# STM32F407ZGT7 register map
File version: 1.0
Registers are 32-bit, access not given, reset 0x0 unless marked. A register's access mark holds for its fields unless they carry their own. Offsets are from the block's base; [hi:lo] are bit positions; {n}, {i} and the like mark numbered series; 'fields as' and 'values as' point back to an identical list.

## USB_OTG_HS
Base 0x40040000
Same registers: USB_OTG_FS 0x50000000
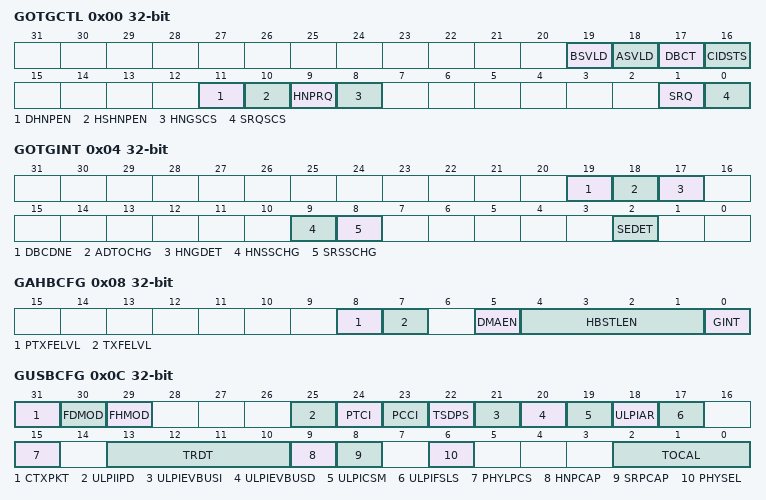
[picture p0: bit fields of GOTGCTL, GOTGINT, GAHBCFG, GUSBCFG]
0x00 GOTGCTL
  [19] BSVLD, [18] ASVLD, [17] DBCT, [16] CIDSTS, [11] DHNPEN, [10] HSHNPEN, [9] HNPRQ, [8] HNGSCS, [1] SRQ, [0] SRQSCS
0x04 GOTGINT
  [19] DBCDNE, [18] ADTOCHG, [17] HNGDET, [9] HNSSCHG, [8] SRSSCHG, [2] SEDET
0x08 GAHBCFG
  [8] PTXFELVL, [7] TXFELVL, [5] DMAEN, [4:1] HBSTLEN, [0] GINT
0x0C GUSBCFG
  [31] CTXPKT, [30] FDMOD, [29] FHMOD, [25] ULPIIPD, [24] PTCI, [23] PCCI, [22] TSDPS, [21] ULPIEVBUSI, [20] ULPIEVBUSD, [19] ULPICSM, [18] ULPIAR, [17] ULPIFSLS, [15] PHYLPCS, [13:10] TRDT, [9] HNPCAP, [8] SRPCAP, [6] PHYSEL, [2:0] TOCAL
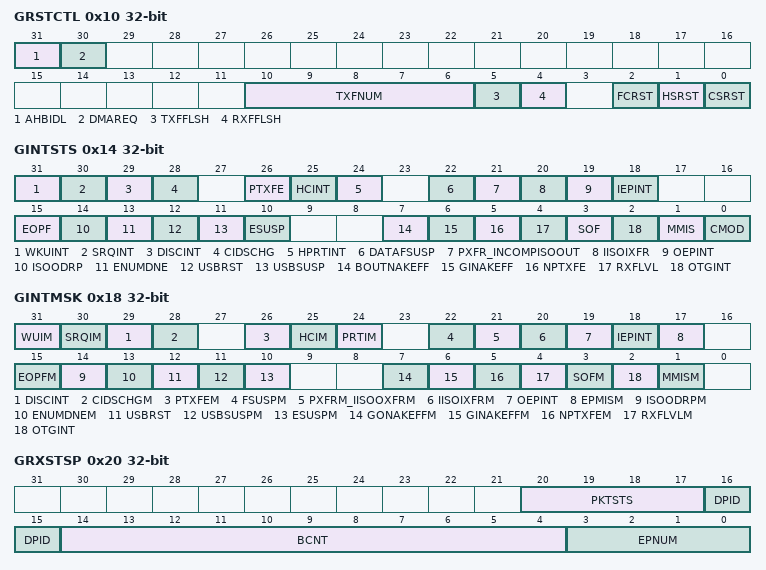
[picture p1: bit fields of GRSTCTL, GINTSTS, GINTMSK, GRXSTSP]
0x10 GRSTCTL
  [31] AHBIDL, [30] DMAREQ, [10:6] TXFNUM, [5] TXFFLSH, [4] RXFFLSH, [2] FCRST, [1] HSRST, [0] CSRST
0x14 GINTSTS
  [31] WKUINT, [30] SRQINT, [29] DISCINT, [28] CIDSCHG, [26] PTXFE, [25] HCINT, [24] HPRTINT, [22] DATAFSUSP, [21] PXFR_INCOMPISOOUT, [20] IISOIXFR, [19] OEPINT, [18] IEPINT, [15] EOPF, [14] ISOODRP, [13] ENUMDNE, [12] USBRST, [11] USBSUSP, [10] ESUSP, [7] BOUTNAKEFF, [6] GINAKEFF, [5] NPTXFE, [4] RXFLVL, [3] SOF, [2] OTGINT, [1] MMIS, [0] CMOD
0x18 GINTMSK
  [31] WUIM, [30] SRQIM, [29] DISCINT, [28] CIDSCHGM, [26] PTXFEM, [25] HCIM, [24] PRTIM, [22] FSUSPM, [21] PXFRM_IISOOXFRM, [20] IISOIXFRM, [19] OEPINT, [18] IEPINT, [17] EPMISM, [15] EOPFM, [14] ISOODRPM, [13] ENUMDNEM, [12] USBRST, [11] USBSUSPM, [10] ESUSPM, [7] GONAKEFFM, [6] GINAKEFFM, [5] NPTXFEM, [4] RXFLVLM, [3] SOFM, [2] OTGINT, [1] MMISM
0x1C GRXSTSR
0x20 GRXSTSP
  [20:17] PKTSTS, [16:15] DPID, [14:4] BCNT, [3:0] EPNUM
0x24 GRXFSIZ
  [15:0] RXFD
0x28 DIEPTXF0_HNPTXFSIZ
0x2C HNPTXSTS
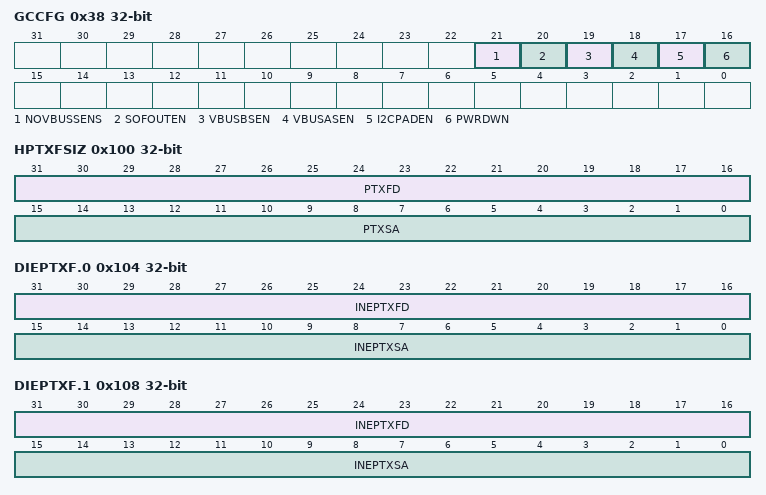
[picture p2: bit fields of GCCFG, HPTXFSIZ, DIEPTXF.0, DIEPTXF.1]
0x38 GCCFG
  [21] NOVBUSSENS, [20] SOFOUTEN, [19] VBUSBSEN, [18] VBUSASEN, [17] I2CPADEN, [16] PWRDWN
0x3C CID
  [31:0] PRODUCT_ID
0x100 HPTXFSIZ
  [31:16] PTXFD, [15:0] PTXSA
0x104 DIEPTXF.0
  [31:16] INEPTXFD, [15:0] INEPTXSA
0x108 DIEPTXF.1
  [31:16] INEPTXFD, [15:0] INEPTXSA
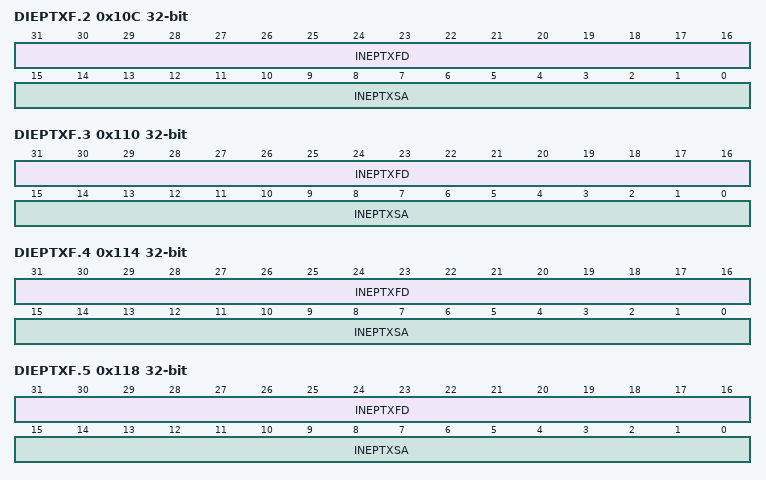
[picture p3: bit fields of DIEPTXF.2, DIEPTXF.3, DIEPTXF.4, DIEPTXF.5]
0x10C DIEPTXF.2
  [31:16] INEPTXFD, [15:0] INEPTXSA
0x110 DIEPTXF.3
  [31:16] INEPTXFD, [15:0] INEPTXSA
0x114 DIEPTXF.4
  [31:16] INEPTXFD, [15:0] INEPTXSA
0x118 DIEPTXF.5
  [31:16] INEPTXFD, [15:0] INEPTXSA
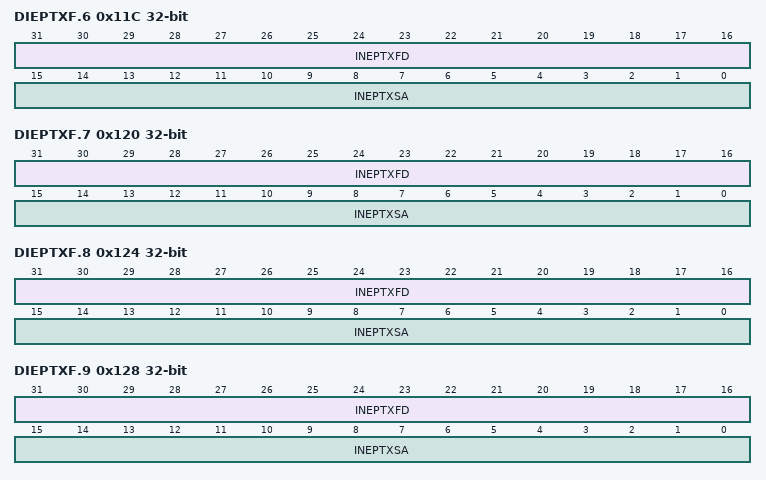
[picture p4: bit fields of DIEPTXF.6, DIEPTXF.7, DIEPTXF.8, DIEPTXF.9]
0x11C DIEPTXF.6
  [31:16] INEPTXFD, [15:0] INEPTXSA
0x120 DIEPTXF.7
  [31:16] INEPTXFD, [15:0] INEPTXSA
0x124 DIEPTXF.8
  [31:16] INEPTXFD, [15:0] INEPTXSA
0x128 DIEPTXF.9
  [31:16] INEPTXFD, [15:0] INEPTXSA
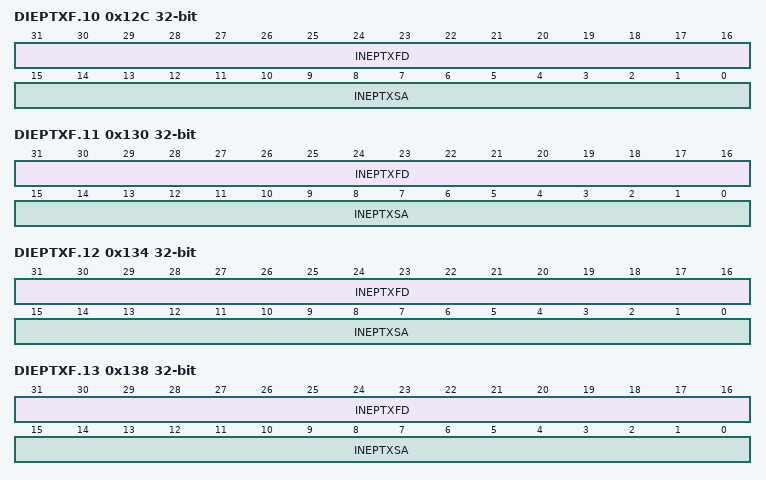
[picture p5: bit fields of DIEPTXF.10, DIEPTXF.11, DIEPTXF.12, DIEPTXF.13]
0x12C DIEPTXF.10
  [31:16] INEPTXFD, [15:0] INEPTXSA
0x130 DIEPTXF.11
  [31:16] INEPTXFD, [15:0] INEPTXSA
0x134 DIEPTXF.12
  [31:16] INEPTXFD, [15:0] INEPTXSA
0x138 DIEPTXF.13
  [31:16] INEPTXFD, [15:0] INEPTXSA
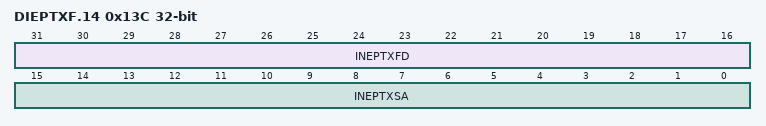
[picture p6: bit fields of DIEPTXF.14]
0x13C DIEPTXF.14
  [31:16] INEPTXFD, [15:0] INEPTXSA

## DCMI
Base 0x50050000
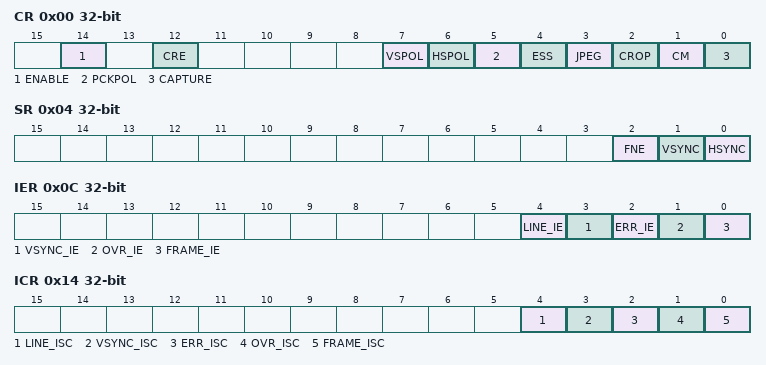
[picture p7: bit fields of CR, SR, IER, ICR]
0x00 CR
  [14] ENABLE, [12] CRE, [7] VSPOL, [6] HSPOL, [5] PCKPOL, [4] ESS, [3] JPEG, [2] CROP, [1] CM, [0] CAPTURE
0x04 SR
  [2] FNE, [1] VSYNC, [0] HSYNC
0x08 RISR
0x0C IER
  [4] LINE_IE, [3] VSYNC_IE, [2] ERR_IE, [1] OVR_IE, [0] FRAME_IE
0x10 MISR
0x14 ICR
  [4] LINE_ISC, [3] VSYNC_ISC, [2] ERR_ISC, [1] OVR_ISC, [0] FRAME_ISC
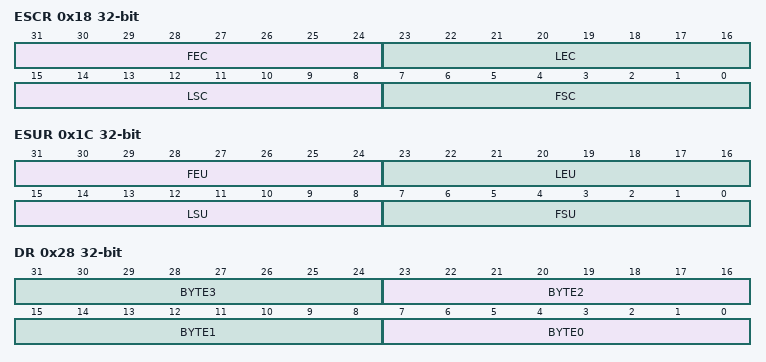
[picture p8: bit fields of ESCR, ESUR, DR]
0x18 ESCR
  [31:24] FEC, [23:16] LEC, [15:8] LSC, [7:0] FSC
0x1C ESUR
  [31:24] FEU, [23:16] LEU, [15:8] LSU, [7:0] FSU
0x20 CWSTRTR
0x24 CWSIZER
0x28 DR
  [8n+7:8n] BYTE{n} (n=0..3)

## RNG
Base 0x50060800
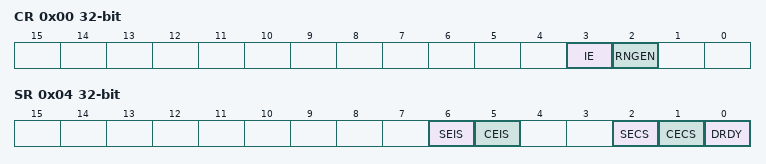
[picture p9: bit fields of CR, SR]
0x00 CR
  [3] IE, [2] RNGEN
0x04 SR
  [6] SEIS, [5] CEIS, [2] SECS, [1] CECS, [0] DRDY
0x08 DR

## FSMC_Bank1
Base 0xA0000000
0x00 BTCR.0
0x04 BTCR.1
0x08 BTCR.2
0x0C BTCR.3
0x10 BTCR.4
0x14 BTCR.5
0x18 BTCR.6
0x1C BTCR.7

## FSMC_Bank2_3
Base 0xA0000060
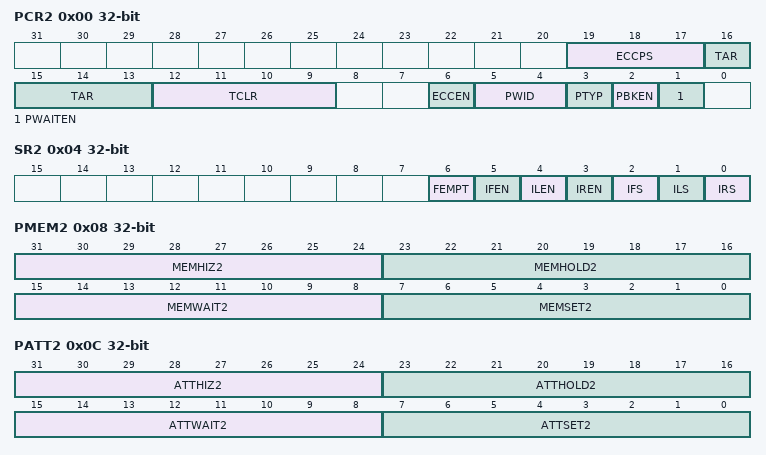
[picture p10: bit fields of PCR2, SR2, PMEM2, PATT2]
0x00 PCR2
  [19:17] ECCPS, [16:13] TAR, [12:9] TCLR, [6] ECCEN, [5:4] PWID, [3] PTYP, [2] PBKEN, [1] PWAITEN
0x04 SR2
  [6] FEMPT, [5] IFEN, [4] ILEN, [3] IREN, [2] IFS, [1] ILS, [0] IRS
0x08 PMEM2
  [31:24] MEMHIZ2, [23:16] MEMHOLD2, [15:8] MEMWAIT2, [7:0] MEMSET2
0x0C PATT2
  [31:24] ATTHIZ2, [23:16] ATTHOLD2, [15:8] ATTWAIT2, [7:0] ATTSET2
0x14 ECCR2
  [31:0] ECC2
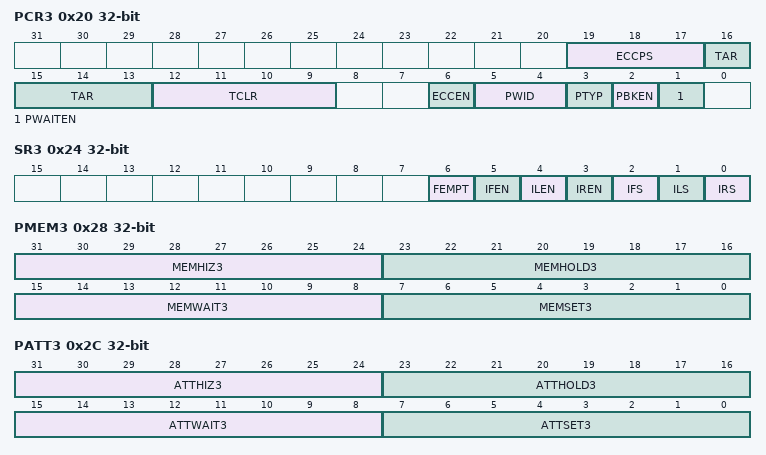
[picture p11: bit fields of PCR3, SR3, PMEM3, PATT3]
0x20 PCR3
  fields as PCR2
0x24 SR3
  [6] FEMPT, [5] IFEN, [4] ILEN, [3] IREN, [2] IFS, [1] ILS, [0] IRS
0x28 PMEM3
  [31:24] MEMHIZ3, [23:16] MEMHOLD3, [15:8] MEMWAIT3, [7:0] MEMSET3
0x2C PATT3
  [31:24] ATTHIZ3, [23:16] ATTHOLD3, [15:8] ATTWAIT3, [7:0] ATTSET3
0x34 ECCR3
  [31:0] ECC3

## FSMC_Bank4
Base 0xA00000A0
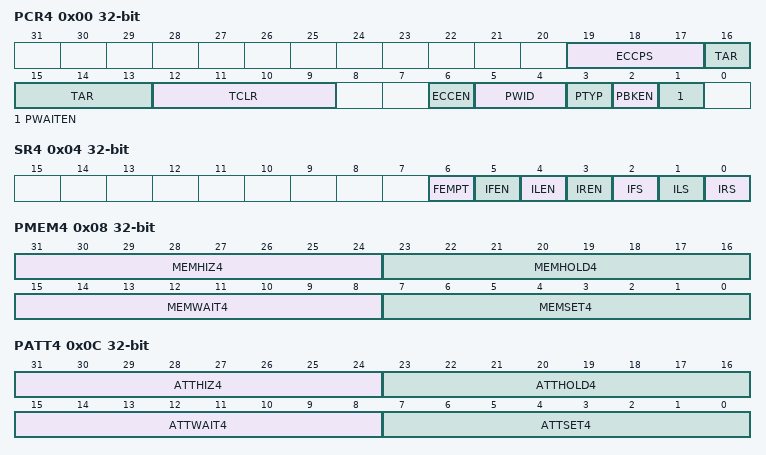
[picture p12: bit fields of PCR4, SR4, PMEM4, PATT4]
0x00 PCR4
  [19:17] ECCPS, [16:13] TAR, [12:9] TCLR, [6] ECCEN, [5:4] PWID, [3] PTYP, [2] PBKEN, [1] PWAITEN
0x04 SR4
  [6] FEMPT, [5] IFEN, [4] ILEN, [3] IREN, [2] IFS, [1] ILS, [0] IRS
0x08 PMEM4
  [31:24] MEMHIZ4, [23:16] MEMHOLD4, [15:8] MEMWAIT4, [7:0] MEMSET4
0x0C PATT4
  [31:24] ATTHIZ4, [23:16] ATTHOLD4, [15:8] ATTWAIT4, [7:0] ATTSET4
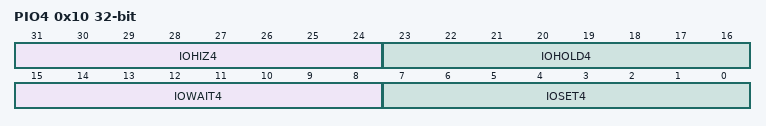
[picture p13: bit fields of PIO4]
0x10 PIO4
  [31:24] IOHIZ4, [23:16] IOHOLD4, [15:8] IOWAIT4, [7:0] IOSET4

## FSMC_Bank1E
Base 0xA0000104
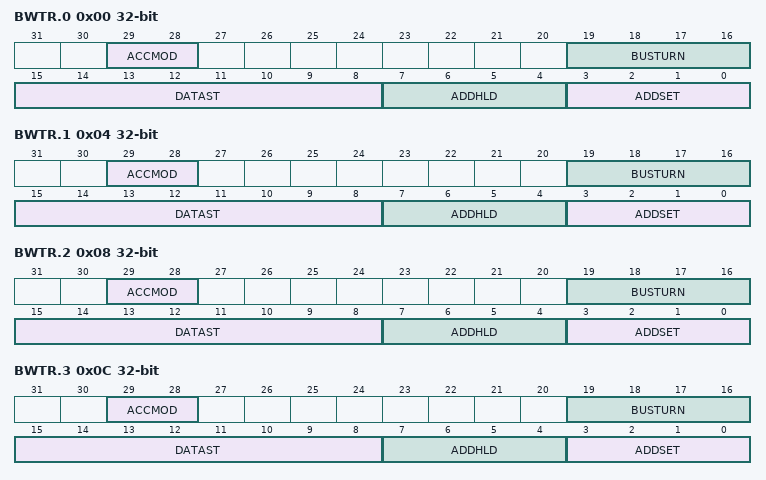
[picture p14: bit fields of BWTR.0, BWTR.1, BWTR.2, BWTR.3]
0x00 BWTR.0
  [29:28] ACCMOD, [19:16] BUSTURN, [15:8] DATAST, [7:4] ADDHLD, [3:0] ADDSET
0x04 BWTR.1
  fields as BWTR.0
0x08 BWTR.2
  fields as BWTR.0
0x0C BWTR.3
  fields as BWTR.0
0x10 BWTR.4
0x14 BWTR.5
0x18 BWTR.6

## DBGMCU
Base 0xE0042000
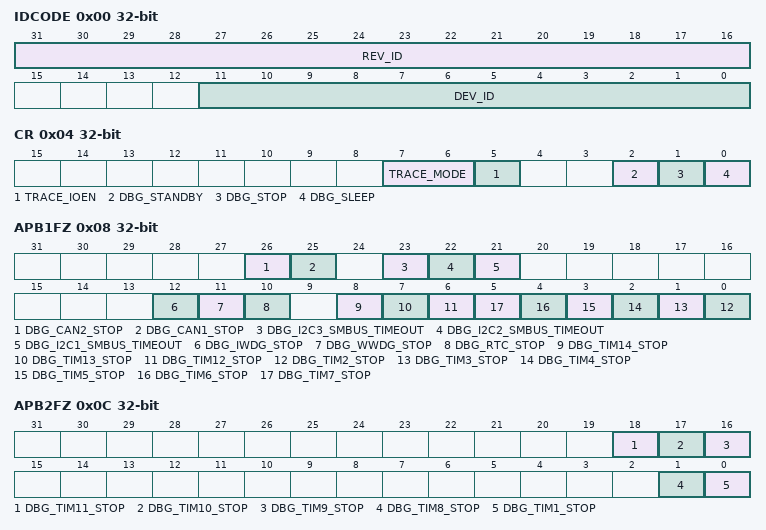
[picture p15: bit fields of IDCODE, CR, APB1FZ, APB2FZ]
0x00 IDCODE
  [31:16] REV_ID, [11:0] DEV_ID
0x04 CR
  [7:6] TRACE_MODE, [5] TRACE_IOEN, [2] DBG_STANDBY, [1] DBG_STOP, [0] DBG_SLEEP
0x08 APB1FZ
  [26] DBG_CAN2_STOP, [25] DBG_CAN1_STOP, [23] DBG_I2C3_SMBUS_TIMEOUT, [22] DBG_I2C2_SMBUS_TIMEOUT, [21] DBG_I2C1_SMBUS_TIMEOUT, [12] DBG_IWDG_STOP, [11] DBG_WWDG_STOP, [10] DBG_RTC_STOP, [8] DBG_TIM14_STOP, [7] DBG_TIM13_STOP, [6] DBG_TIM12_STOP, [n-2] DBG_TIM{n}_STOP (n=2..7)
0x0C APB2FZ
  [18] DBG_TIM11_STOP, [17] DBG_TIM10_STOP, [16] DBG_TIM9_STOP, [1] DBG_TIM8_STOP, [0] DBG_TIM1_STOP
